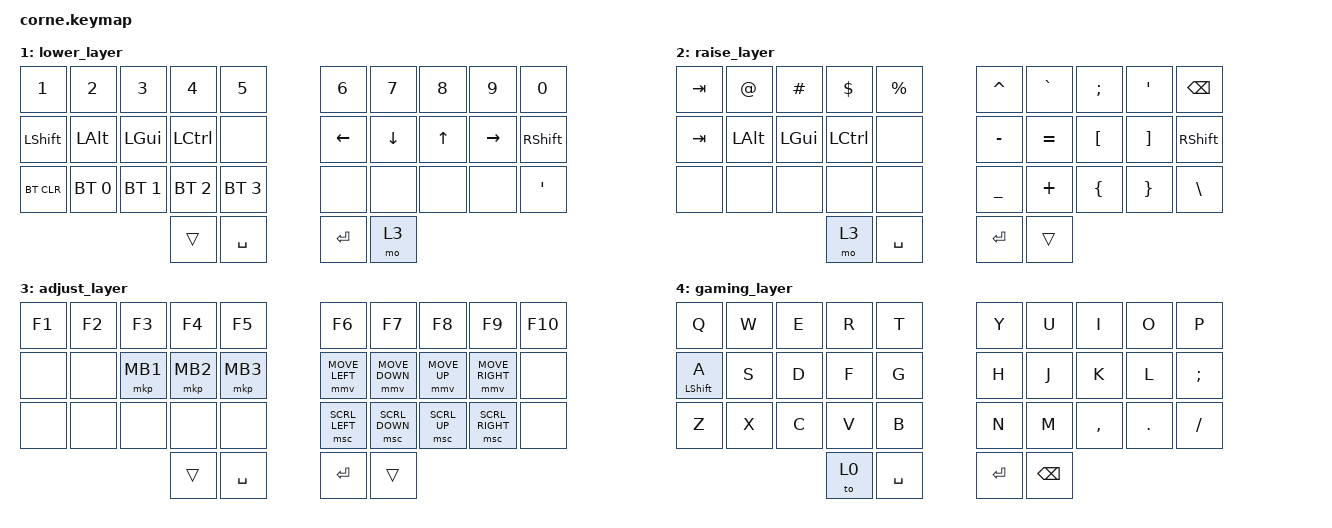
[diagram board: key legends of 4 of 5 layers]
/*
 * Copyright (c) 2020 The ZMK Contributors
 *
 * SPDX-License-Identifier: MIT
 */

#include <behaviors.dtsi>
#include <dt-bindings/zmk/keys.h>
#include <dt-bindings/zmk/bt.h>

#define ZMK_POINTING_DEFAULT_MOVE_VAL 1000  // default: 600
#define ZMK_POINTING_DEFAULT_SCRL_VAL 20    // default: 10
#include <dt-bindings/zmk/pointing.h>

/ {
    behaviors {
        hm: homerow_mods {
            compatible = "zmk,behavior-hold-tap";
            #binding-cells = <2>;
            tapping-term-ms = <200>;
            quick-tap-ms = <175>;
            require-prior-idle-ms = <1>;
            retro-tap;
            flavor = "balanced";
            bindings = <&kp>, <&kp>;
        };
    };
        custom_lt: layer_tap {
            compatible = "zmk,behavior-hold-tap";
            #binding-cells = <2>;
            tapping-term-ms = <200>;
            quick-tap-ms = <175>;
            require-prior-idle-ms = <1>;
            retro-tap;
            flavor = "balanced";
            bindings = <&mo>, <&kp>;
        };

    combos {
        compatible = "zmk,combos";
        combo_gaming {
            timeout-ms = <50>;
            key-positions = <1 5 6 10>;    // Q, T, Y, P keys
            bindings = <&to 4>;
        };
    };

        keymap {
                compatible = "zmk,keymap";

                default_layer {
// -----------------------------------------------------------------------------------------
// |     |  Q  |  W  |  E  |  R  |  T  |   |  Y  |  U   |  I  |  O  |  P  |     |
// |     |  A  |  S  |  D  |  F  |  G  |   |  H  |  J   |  K  |  L  |  ;  |     |
// |     |  Z  |  X  |  C  |  V  |  B  |   |  N  |  M   |  ,  |  .  |  /  |     |
//                   | CAPS| SPC |   | ENT | BSPC |
                        bindings = <
   &kp Q       &kp W      &kp E       &kp R       &kp T         &kp Y    &kp U       &kp I       &kp O      &kp P
   &hm LSHFT A &hm RALT S &hm LGUI D  &hm LCTRL F &kp G         &kp H    &hm RCTRL J &hm RGUI K  &hm RALT L &hm RSHFT SEMI
   &kp Z       &kp X      &kp C       &kp V       &kp B         &kp N    &kp M       &kp COMMA   &kp DOT    &kp FSLH  &none
                         &custom_lt 1 CAPS   &kp SPACE                 &kp RET  &custom_lt 2 BSPC
                        >;
                };

                lower_layer {
                        bindings = <
   &kp N1     &kp N2        &kp N3        &kp N4        &kp N5          &kp N6    &kp N7    &kp N8    &kp N9    &kp N0
   &kp LSHFT  &kp LALT      &kp LGUI      &kp LCTRL     &none           &kp LEFT  &kp DOWN  &kp UP    &kp RIGHT &kp RSHFT
   &bt BT_CLR &bt BT_SEL 0  &bt BT_SEL 1  &bt BT_SEL 2  &bt BT_SEL 3    &none     &none     &none     &none     &kp SQT
                        &trans         &kp SPACE                     &kp RET   &mo 3
                        >;
                };

                raise_layer {
                        bindings = <
   &kp TAB   &kp AT    &kp HASH  &kp DLLR  &kp PRCNT    &kp CARET &kp GRAVE &kp SEMI  &kp SQT   &kp BSPC
   &kp TAB   &kp LALT  &kp LGUI  &kp LCTRL &none        &kp MINUS &kp EQUAL &kp LBKT  &kp RBKT  &kp RSHFT
   &none     &none     &none     &none     &none        &kp UNDER &kp PLUS  &kp LBRC  &kp RBRC  &kp BSLH
                       &mo 3 &kp SPACE              &kp RET   &trans
                        >;
                };

                adjust_layer {
                        bindings = <
   &kp F1    &kp F2    &kp F3    &kp F4    &kp F5       &kp F6    &kp F7    &kp F8    &kp F9    &kp F10
   &none     &none     &mkp MB1  &mkp MB2  &mkp MB3     &mmv MOVE_LEFT &mmv MOVE_DOWN &mmv MOVE_UP &mmv MOVE_RIGHT &none
   &none     &none     &none     &none     &none        &msc SCRL_LEFT &msc SCRL_DOWN &msc SCRL_UP &msc SCRL_RIGHT &none
                       &trans    &kp SPACE               &kp RET   &trans
                        >;
                };

                gaming_layer {
// -----------------------------------------------------------------------------------------
// |     |  Q  |  W  |  E  |  R  |  T  |   |  Y  |  U   |  I  |  O  |  P  |     |
// |     |  A  |  S  |  D  |  F  |  G  |   |  H  |  J   |  K  |  L  |  ;  |     |
// |     |  Z  |  X  |  C  |  V  |  B  |   |  N  |  M   |  ,  |  .  |  /  |     |
//                   |TO(0)| SPC |   | ENT | BSPC |
                        bindings = <
   &kp Q     &kp W      &kp E       &kp R       &kp T         &kp Y    &kp U       &kp I       &kp O      &kp P
   &hm LSHFT A &kp S      &kp D       &kp F       &kp G         &kp H    &kp J       &kp K       &kp L      &kp SEMI
   &kp Z     &kp X      &kp C       &kp V       &kp B         &kp N    &kp M       &kp COMMA   &kp DOT    &kp FSLH
                       &to 0        &kp SPACE                 &kp RET  &kp BSPC
                        >;
                };
        };
};
